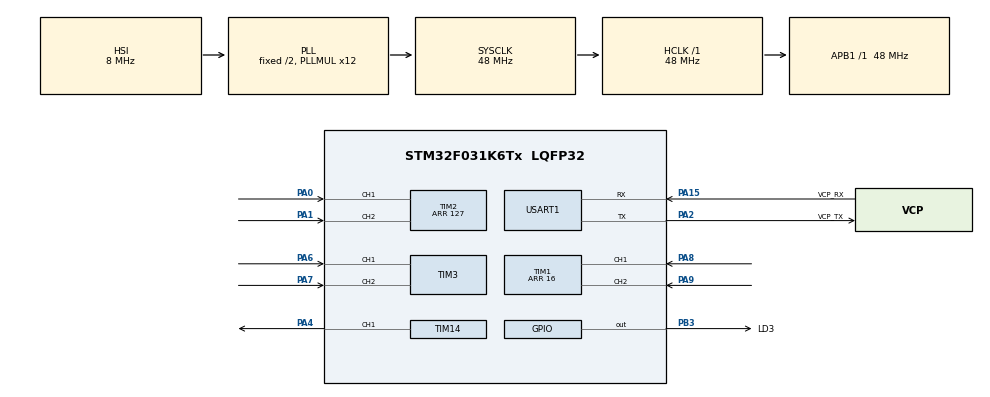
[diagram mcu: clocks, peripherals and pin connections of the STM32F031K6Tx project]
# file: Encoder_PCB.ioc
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Mcu.Family=STM32F0
Mcu.Name=STM32F031K6Tx
Mcu.Package=LQFP32
NVIC.TIM14_IRQn=true\:0\:0\:false\:false\:true\:true
PA0.GPIO_PuPd=GPIO_PULLUP
PA0.Signal=S_TIM2_CH1_ETR
PA1.GPIO_PuPd=GPIO_PULLUP
PA1.Signal=S_TIM2_CH2
PA13.GPIO_Label=SWDIO
PA13.Mode=Serial_Wire
PA13.Signal=SYS_SWDIO
PA14.GPIO_Label=SWCLK
PA14.Mode=Serial_Wire
PA14.Signal=SYS_SWCLK
PA15.GPIO_Label=VCP_RX
PA15.Mode=Asynchronous
PA15.Signal=USART1_RX
PA2.GPIO_Label=VCP_TX
PA2.Mode=Asynchronous
PA2.Signal=USART1_TX
PA4.GPIO_Speed=GPIO_SPEED_FREQ_HIGH
PA4.Signal=S_TIM14_CH1
PA6.Signal=S_TIM3_CH1
PA7.Signal=S_TIM3_CH2
PA8.GPIO_PuPd=GPIO_PULLUP
PA8.Signal=S_TIM1_CH1
PA9.GPIO_PuPd=GPIO_PULLUP
PA9.Signal=S_TIM1_CH2
PB3.GPIO_Label=LD3
PB3.Signal=GPIO_Output
PF0-OSC_IN.Mode=HSE-External-Clock-Source
PF0-OSC_IN.Signal=RCC_OSC_IN
ProjectManager.HeapSize=0x200
ProjectManager.StackSize=0x400
ProjectManager.TargetToolchain=SW4STM32
RCC.AHBFreq_Value=48000000
RCC.APB1Freq_Value=48000000
RCC.APB1TimFreq_Value=48000000
RCC.HCLKFreq_Value=48000000
RCC.PLLMUL=RCC_PLL_MUL12
RCC.SYSCLKFreq_VALUE=48000000
RCC.SYSCLKSource=RCC_SYSCLKSOURCE_PLLCLK
SH.S_TIM14_CH1.0=TIM14_CH1,PWM Generation1 CH1
SH.S_TIM1_CH1.0=TIM1_CH1,Encoder_Interface
SH.S_TIM1_CH2.0=TIM1_CH2,Encoder_Interface
SH.S_TIM2_CH1_ETR.0=TIM2_CH1,Encoder_Interface
SH.S_TIM2_CH2.0=TIM2_CH2,Encoder_Interface
SH.S_TIM3_CH1.0=TIM3_CH1,Encoder_Interface
SH.S_TIM3_CH2.0=TIM3_CH2,Encoder_Interface
TIM1.EncoderMode=TIM_ENCODERMODE_TI12
TIM1.IC1Filter=5
TIM1.Period=16
TIM14.Channel=TIM_CHANNEL_1
TIM14.OCFastMode_PWM=TIM_OCFAST_ENABLE
TIM14.Period=47999
TIM14.Prescaler=999
TIM14.Pulse=23999
TIM2.EncoderMode=TIM_ENCODERMODE_TI12
TIM2.IC1Filter=10
TIM2.IC1Polarity=TIM_ICPOLARITY_RISING
TIM2.IC2Filter=10
TIM2.IC2Polarity=TIM_ICPOLARITY_RISING
TIM2.Period=127
USART1.VirtualMode-Asynchronous=VM_ASYNC
USART1.WordLength=WORDLENGTH_8B
VP_TIM14_VS_ClockSourceINT.Mode=Enable_Timer
VP_TIM16_VS_ClockSourceINT.Mode=Enable_Timer
VP_TIM17_VS_ClockSourceINT.Mode=Enable_Timer
board=NUCLEO-F031K6

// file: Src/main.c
/**
  ******************************************************************************
  * @file           : main.c
  * @brief          : Main program body
  ******************************************************************************
  ** This notice applies to any and all portions of this file
  * that are not between comment pairs USER CODE BEGIN and
  * USER CODE END. Other portions of this file, whether
  * inserted by the user or by software development tools
  * are owned by their respective copyright owners.
  *
  * COPYRIGHT(c) 2019 STMicroelectronics
  *
  * Redistribution and use in source and binary forms, with or without modification,
  * are permitted provided that the following conditions are met:
  *   1. Redistributions of source code must retain the above copyright notice,
  *      this list of conditions and the following disclaimer.
  *   2. Redistributions in binary form must reproduce the above copyright notice,
  *      this list of conditions and the following disclaimer in the documentation
  *      and/or other materials provided with the distribution.
  *   3. Neither the name of STMicroelectronics nor the names of its contributors
  *      may be used to endorse or promote products derived from this software
  *      without specific prior written permission.
  *
  * THIS SOFTWARE IS PROVIDED BY THE COPYRIGHT HOLDERS AND CONTRIBUTORS "AS IS"
  * AND ANY EXPRESS OR IMPLIED WARRANTIES, INCLUDING, BUT NOT LIMITED TO, THE
  * IMPLIED WARRANTIES OF MERCHANTABILITY AND FITNESS FOR A PARTICULAR PURPOSE ARE
  * DISCLAIMED. IN NO EVENT SHALL THE COPYRIGHT HOLDER OR CONTRIBUTORS BE LIABLE
  * FOR ANY DIRECT, INDIRECT, INCIDENTAL, SPECIAL, EXEMPLARY, OR CONSEQUENTIAL
  * DAMAGES (INCLUDING, BUT NOT LIMITED TO, PROCUREMENT OF SUBSTITUTE GOODS OR
  * SERVICES; LOSS OF USE, DATA, OR PROFITS; OR BUSINESS INTERRUPTION) HOWEVER
  * CAUSED AND ON ANY THEORY OF LIABILITY, WHETHER IN CONTRACT, STRICT LIABILITY,
  * OR TORT (INCLUDING NEGLIGENCE OR OTHERWISE) ARISING IN ANY WAY OUT OF THE USE
  * OF THIS SOFTWARE, EVEN IF ADVISED OF THE POSSIBILITY OF SUCH DAMAGE.
  *
  ******************************************************************************
  */
#include "main.h"
#include "stm32f0xx_hal.h"

TIM_HandleTypeDef htim1;
TIM_HandleTypeDef htim2;
TIM_HandleTypeDef htim3;
TIM_HandleTypeDef htim14;
TIM_HandleTypeDef htim16;
TIM_HandleTypeDef htim17;

UART_HandleTypeDef huart1;

/* USER CODE BEGIN PV */
/* Private variables ---------------------------------------------------------*/

/* USER CODE END PV */

void SystemClock_Config(void);
static void MX_GPIO_Init(void);
static void MX_USART1_UART_Init(void);
static void MX_TIM1_Init(void);
static void MX_TIM2_Init(void);
static void MX_TIM3_Init(void);
static void MX_TIM14_Init(void);
static void MX_TIM16_Init(void);
static void MX_TIM17_Init(void);

void HAL_TIM_MspPostInit(TIM_HandleTypeDef *htim);

/* USER CODE BEGIN PFP */
/* Private function prototypes -----------------------------------------------*/

/* USER CODE END PFP */

int main(void)
{

  /* MCU Configuration----------------------------------------------------------*/

  /* Reset of all peripherals, Initializes the Flash interface and the Systick. */
  HAL_Init();

  /* Configure the system clock */
  SystemClock_Config();

  /* Initialize all configured peripherals */
  MX_GPIO_Init();
  MX_USART1_UART_Init();
  MX_TIM1_Init();
  MX_TIM2_Init();
  MX_TIM3_Init();
  MX_TIM14_Init();
  MX_TIM16_Init();
  MX_TIM17_Init();
  /* USER CODE BEGIN 2 */
  HAL_TIM_Encoder_Start(&htim2,TIM_CHANNEL_ALL);
  HAL_TIM_PWM_Start(&htim14, TIM_CHANNEL_1);
  uint8_t i = 0;
  char transmit[5];
  /* USER CODE END 2 */

  /* Infinite loop */
  while (1)
  {

  /* USER CODE BEGIN 3 */
	  HAL_GPIO_TogglePin(LD3_GPIO_Port, LD3_Pin);
	  //HAL_Delay(i);
	  i = TIM2->CNT;

	  transmit[0]='p';
	  transmit[1]='=';
	  transmit[2]=i;
	  transmit[3]='\r';
	  transmit[4]='\n';

	  __HAL_TIM_SET_COMPARE(&htim14, TIM_CHANNEL_1, i*10);
	  HAL_UART_Transmit(&huart1, transmit, 5, 0xFFFF);

  }

  /* USER CODE END 3 */

}

void SystemClock_Config(void)
{

  RCC_OscInitTypeDef RCC_OscInitStruct;
  RCC_ClkInitTypeDef RCC_ClkInitStruct;
  RCC_PeriphCLKInitTypeDef PeriphClkInit;

    /**Initializes the CPU, AHB and APB busses clocks
    */
  RCC_OscInitStruct.OscillatorType = RCC_OSCILLATORTYPE_HSI;
  RCC_OscInitStruct.HSIState = RCC_HSI_ON;
  RCC_OscInitStruct.HSICalibrationValue = 16;
  RCC_OscInitStruct.PLL.PLLState = RCC_PLL_ON;
  RCC_OscInitStruct.PLL.PLLSource = RCC_PLLSOURCE_HSI;
  RCC_OscInitStruct.PLL.PLLMUL = RCC_PLL_MUL12;
  RCC_OscInitStruct.PLL.PREDIV = RCC_PREDIV_DIV1;
  if (HAL_RCC_OscConfig(&RCC_OscInitStruct) != HAL_OK)
  {
    _Error_Handler(__FILE__, __LINE__);
  }

    /**Initializes the CPU, AHB and APB busses clocks
    */
  RCC_ClkInitStruct.ClockType = RCC_CLOCKTYPE_HCLK|RCC_CLOCKTYPE_SYSCLK
                              |RCC_CLOCKTYPE_PCLK1;
  RCC_ClkInitStruct.SYSCLKSource = RCC_SYSCLKSOURCE_PLLCLK;
  RCC_ClkInitStruct.AHBCLKDivider = RCC_SYSCLK_DIV1;
  RCC_ClkInitStruct.APB1CLKDivider = RCC_HCLK_DIV1;

  if (HAL_RCC_ClockConfig(&RCC_ClkInitStruct, FLASH_LATENCY_1) != HAL_OK)
  {
    _Error_Handler(__FILE__, __LINE__);
  }

  PeriphClkInit.PeriphClockSelection = RCC_PERIPHCLK_USART1;
  PeriphClkInit.Usart1ClockSelection = RCC_USART1CLKSOURCE_PCLK1;
  if (HAL_RCCEx_PeriphCLKConfig(&PeriphClkInit) != HAL_OK)
  {
    _Error_Handler(__FILE__, __LINE__);
  }

    /**Configure the Systick interrupt time
    */
  HAL_SYSTICK_Config(HAL_RCC_GetHCLKFreq()/1000);

    /**Configure the Systick
    */
  HAL_SYSTICK_CLKSourceConfig(SYSTICK_CLKSOURCE_HCLK);

  /* SysTick_IRQn interrupt configuration */
  HAL_NVIC_SetPriority(SysTick_IRQn, 0, 0);
}

/* TIM1 init function */
static void MX_TIM1_Init(void)
{

  TIM_Encoder_InitTypeDef sConfig;
  TIM_MasterConfigTypeDef sMasterConfig;

  htim1.Instance = TIM1;
  htim1.Init.Prescaler = 0;
  htim1.Init.CounterMode = TIM_COUNTERMODE_UP;
  htim1.Init.Period = 16;
  htim1.Init.ClockDivision = TIM_CLOCKDIVISION_DIV1;
  htim1.Init.RepetitionCounter = 0;
  htim1.Init.AutoReloadPreload = TIM_AUTORELOAD_PRELOAD_DISABLE;
  sConfig.EncoderMode = TIM_ENCODERMODE_TI12;
  sConfig.IC1Polarity = TIM_ICPOLARITY_RISING;
  sConfig.IC1Selection = TIM_ICSELECTION_DIRECTTI;
  sConfig.IC1Prescaler = TIM_ICPSC_DIV1;
  sConfig.IC1Filter = 5;
  sConfig.IC2Polarity = TIM_ICPOLARITY_RISING;
  sConfig.IC2Selection = TIM_ICSELECTION_DIRECTTI;
  sConfig.IC2Prescaler = TIM_ICPSC_DIV1;
  sConfig.IC2Filter = 0;
  if (HAL_TIM_Encoder_Init(&htim1, &sConfig) != HAL_OK)
  {
    _Error_Handler(__FILE__, __LINE__);
  }

  sMasterConfig.MasterOutputTrigger = TIM_TRGO_RESET;
  sMasterConfig.MasterSlaveMode = TIM_MASTERSLAVEMODE_DISABLE;
  if (HAL_TIMEx_MasterConfigSynchronization(&htim1, &sMasterConfig) != HAL_OK)
  {
    _Error_Handler(__FILE__, __LINE__);
  }

}

/* TIM2 init function */
static void MX_TIM2_Init(void)
{

  TIM_Encoder_InitTypeDef sConfig;
  TIM_MasterConfigTypeDef sMasterConfig;

  htim2.Instance = TIM2;
  htim2.Init.Prescaler = 0;
  htim2.Init.CounterMode = TIM_COUNTERMODE_UP;
  htim2.Init.Period = 127;
  htim2.Init.ClockDivision = TIM_CLOCKDIVISION_DIV1;
  htim2.Init.AutoReloadPreload = TIM_AUTORELOAD_PRELOAD_DISABLE;
  sConfig.EncoderMode = TIM_ENCODERMODE_TI12;
  sConfig.IC1Polarity = TIM_ICPOLARITY_RISING;
  sConfig.IC1Selection = TIM_ICSELECTION_DIRECTTI;
  sConfig.IC1Prescaler = TIM_ICPSC_DIV1;
  sConfig.IC1Filter = 10;
  sConfig.IC2Polarity = TIM_ICPOLARITY_RISING;
  sConfig.IC2Selection = TIM_ICSELECTION_DIRECTTI;
  sConfig.IC2Prescaler = TIM_ICPSC_DIV1;
  sConfig.IC2Filter = 10;
  if (HAL_TIM_Encoder_Init(&htim2, &sConfig) != HAL_OK)
  {
    _Error_Handler(__FILE__, __LINE__);
  }

  sMasterConfig.MasterOutputTrigger = TIM_TRGO_RESET;
  sMasterConfig.MasterSlaveMode = TIM_MASTERSLAVEMODE_DISABLE;
  if (HAL_TIMEx_MasterConfigSynchronization(&htim2, &sMasterConfig) != HAL_OK)
  {
    _Error_Handler(__FILE__, __LINE__);
  }

}

/* TIM3 init function */
static void MX_TIM3_Init(void)
{

  TIM_Encoder_InitTypeDef sConfig;
  TIM_MasterConfigTypeDef sMasterConfig;

  htim3.Instance = TIM3;
  htim3.Init.Prescaler = 0;
  htim3.Init.CounterMode = TIM_COUNTERMODE_UP;
  htim3.Init.Period = 0;
  htim3.Init.ClockDivision = TIM_CLOCKDIVISION_DIV1;
  htim3.Init.AutoReloadPreload = TIM_AUTORELOAD_PRELOAD_DISABLE;
  sConfig.EncoderMode = TIM_ENCODERMODE_TI1;
  sConfig.IC1Polarity = TIM_ICPOLARITY_RISING;
  sConfig.IC1Selection = TIM_ICSELECTION_DIRECTTI;
  sConfig.IC1Prescaler = TIM_ICPSC_DIV1;
  sConfig.IC1Filter = 0;
  sConfig.IC2Polarity = TIM_ICPOLARITY_RISING;
  sConfig.IC2Selection = TIM_ICSELECTION_DIRECTTI;
  sConfig.IC2Prescaler = TIM_ICPSC_DIV1;
  sConfig.IC2Filter = 0;
  if (HAL_TIM_Encoder_Init(&htim3, &sConfig) != HAL_OK)
  {
    _Error_Handler(__FILE__, __LINE__);
  }

  sMasterConfig.MasterOutputTrigger = TIM_TRGO_RESET;
  sMasterConfig.MasterSlaveMode = TIM_MASTERSLAVEMODE_DISABLE;
  if (HAL_TIMEx_MasterConfigSynchronization(&htim3, &sMasterConfig) != HAL_OK)
  {
    _Error_Handler(__FILE__, __LINE__);
  }

}

/* TIM14 init function */
static void MX_TIM14_Init(void)
{

  TIM_OC_InitTypeDef sConfigOC;

  htim14.Instance = TIM14;
  htim14.Init.Prescaler = 999;
  htim14.Init.CounterMode = TIM_COUNTERMODE_UP;
  htim14.Init.Period = 47999;
  htim14.Init.ClockDivision = TIM_CLOCKDIVISION_DIV1;
  htim14.Init.AutoReloadPreload = TIM_AUTORELOAD_PRELOAD_DISABLE;
  if (HAL_TIM_Base_Init(&htim14) != HAL_OK)
  {
    _Error_Handler(__FILE__, __LINE__);
  }

  if (HAL_TIM_PWM_Init(&htim14) != HAL_OK)
  {
    _Error_Handler(__FILE__, __LINE__);
  }

  sConfigOC.OCMode = TIM_OCMODE_PWM1;
  sConfigOC.Pulse = 23999;
  sConfigOC.OCPolarity = TIM_OCPOLARITY_HIGH;
  sConfigOC.OCFastMode = TIM_OCFAST_ENABLE;
  if (HAL_TIM_PWM_ConfigChannel(&htim14, &sConfigOC, TIM_CHANNEL_1) != HAL_OK)
  {
    _Error_Handler(__FILE__, __LINE__);
  }

  HAL_TIM_MspPostInit(&htim14);

}

/* TIM16 init function */
static void MX_TIM16_Init(void)
{

  htim16.Instance = TIM16;
  htim16.Init.Prescaler = 0;
  htim16.Init.CounterMode = TIM_COUNTERMODE_UP;
  htim16.Init.Period = 0;
  htim16.Init.ClockDivision = TIM_CLOCKDIVISION_DIV1;
  htim16.Init.RepetitionCounter = 0;
  htim16.Init.AutoReloadPreload = TIM_AUTORELOAD_PRELOAD_DISABLE;
  if (HAL_TIM_Base_Init(&htim16) != HAL_OK)
  {
    _Error_Handler(__FILE__, __LINE__);
  }

}

/* TIM17 init function */
static void MX_TIM17_Init(void)
{

  htim17.Instance = TIM17;
  htim17.Init.Prescaler = 0;
  htim17.Init.CounterMode = TIM_COUNTERMODE_UP;
  htim17.Init.Period = 0;
  htim17.Init.ClockDivision = TIM_CLOCKDIVISION_DIV1;
  htim17.Init.RepetitionCounter = 0;
  htim17.Init.AutoReloadPreload = TIM_AUTORELOAD_PRELOAD_DISABLE;
  if (HAL_TIM_Base_Init(&htim17) != HAL_OK)
  {
    _Error_Handler(__FILE__, __LINE__);
  }

}

/* USART1 init function */
static void MX_USART1_UART_Init(void)
{

  huart1.Instance = USART1;
  huart1.Init.BaudRate = 38400;
  huart1.Init.WordLength = UART_WORDLENGTH_8B;
  huart1.Init.StopBits = UART_STOPBITS_1;
  huart1.Init.Parity = UART_PARITY_NONE;
  huart1.Init.Mode = UART_MODE_TX_RX;
  huart1.Init.HwFlowCtl = UART_HWCONTROL_NONE;
  huart1.Init.OverSampling = UART_OVERSAMPLING_16;
  huart1.Init.OneBitSampling = UART_ONE_BIT_SAMPLE_DISABLE;
  huart1.AdvancedInit.AdvFeatureInit = UART_ADVFEATURE_NO_INIT;
  if (HAL_UART_Init(&huart1) != HAL_OK)
  {
    _Error_Handler(__FILE__, __LINE__);
  }

}

/** Configure pins as
        * Analog
        * Input
        * Output
        * EVENT_OUT
        * EXTI
*/
static void MX_GPIO_Init(void)
{

  GPIO_InitTypeDef GPIO_InitStruct;

  /* GPIO Ports Clock Enable */
  __HAL_RCC_GPIOF_CLK_ENABLE();
  __HAL_RCC_GPIOA_CLK_ENABLE();
  __HAL_RCC_GPIOB_CLK_ENABLE();

  /*Configure GPIO pin Output Level */
  HAL_GPIO_WritePin(LD3_GPIO_Port, LD3_Pin, GPIO_PIN_RESET);

  /*Configure GPIO pin : LD3_Pin */
  GPIO_InitStruct.Pin = LD3_Pin;
  GPIO_InitStruct.Mode = GPIO_MODE_OUTPUT_PP;
  GPIO_InitStruct.Pull = GPIO_NOPULL;
  GPIO_InitStruct.Speed = GPIO_SPEED_FREQ_LOW;
  HAL_GPIO_Init(LD3_GPIO_Port, &GPIO_InitStruct);

}

void _Error_Handler(char *file, int line)
{
  while(1)
  {
  }
}

/************************ (C) COPYRIGHT STMicroelectronics *****END OF FILE****/
